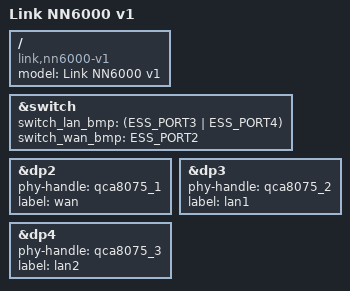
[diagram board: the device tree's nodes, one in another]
// SPDX-License-Identifier: GPL-2.0-or-later OR MIT
//
// 连我 NN6000 V1 (Link NN6000 v1)：双 LAN + WAN
// 适配基底: immortalwrt openwrt-25.12；来源: immortalwrt master 的 ipq6000-nn6000-v1.dts

/dts-v1/;

#include "ipq6000-link.dtsi"

/ {
	model = "Link NN6000 v1";
	compatible = "link,nn6000-v1", "qcom,ipq6018";
};

&switch {
	switch_lan_bmp = <(ESS_PORT3 | ESS_PORT4)>;
	switch_wan_bmp = <ESS_PORT2>;
};

&dp2 {
	status = "okay";
	phy-handle = <&qca8075_1>;
	label = "wan";
};

&dp3 {
	status = "okay";
	phy-handle = <&qca8075_2>;
	label = "lan1";
};

&dp4 {
	status = "okay";
	phy-handle = <&qca8075_3>;
	label = "lan2";
};
